# STM32F101 register map
File version: 1.2
CPU: CM3 r1p1, little endian, no MPU, no FPU, 4 interrupt priority bits
Registers are 32-bit, read-write, reset 0x0 unless marked. A register's access mark holds for its fields unless they carry their own. Offsets are from the block's base; [hi:lo] are bit positions; {n}, {i} and the like mark numbered series.

## USB — Universal serial bus full-speed device interface
Base 0x40005C00
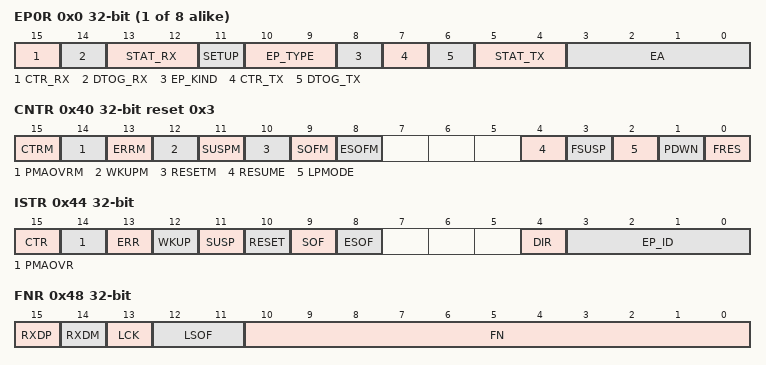
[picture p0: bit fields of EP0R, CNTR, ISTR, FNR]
{0x0+4i} EP{i}R (i=0..7) — endpoint {i} register
  [15] CTR_RX — Correct transfer for reception
  [14] DTOG_RX — Data Toggle, for reception transfers
  [13:12] STAT_RX — Status bits, for reception transfers
  [11] SETUP — Setup transaction completed
  [10:9] EP_TYPE — Endpoint type
  [8] EP_KIND — Endpoint kind
  [7] CTR_TX — Correct Transfer for transmission
  [6] DTOG_TX — Data Toggle, for transmission transfers
  [5:4] STAT_TX — Status bits, for transmission transfers
  [3:0] EA — Endpoint address
0x40 CNTR reset 0x3 — control register
  [15] CTRM — Correct transfer interrupt mask
  [14] PMAOVRM — Packet memory area over / underrun interrupt mask
  [13] ERRM — Error interrupt mask
  [12] WKUPM — Wakeup interrupt mask
  [11] SUSPM — Suspend mode interrupt mask
  [10] RESETM — USB reset interrupt mask
  [9] SOFM — Start of frame interrupt mask
  [8] ESOFM — Expected start of frame interrupt mask
  [4] RESUME — Resume request
  [3] FSUSP — Force suspend
  [2] LPMODE — Low-power mode
  [1] PDWN — Power down
  [0] FRES — Force USB Reset
0x44 ISTR — interrupt status register
  [15] CTR — Correct transfer
  [14] PMAOVR — Packet memory area over / underrun
  [13] ERR — Error
  [12] WKUP — Wakeup
  [11] SUSP — Suspend mode request
  [10] RESET — reset request
  [9] SOF — start of frame
  [8] ESOF — Expected start frame
  [4] DIR — Direction of transaction
  [3:0] EP_ID — Endpoint Identifier
0x48 FNR ro — frame number register
  [15] RXDP — Receive data + line status
  [14] RXDM — Receive data - line status
  [13] LCK — Locked
  [12:11] LSOF — Lost SOF
  [10:0] FN — Frame number
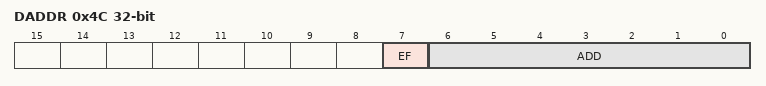
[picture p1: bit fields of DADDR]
0x4C DADDR — device address
  [7] EF — Enable function
  [6:0] ADD — Device address
0x50 BTABLE — Buffer table address
  [15:3] BTABLE — Buffer table

## SDIO — Secure digital input/output interface
Base 0x40018000
0x00 POWER — Bits 1:0 = PWRCTRL: Power supply control bits
  [1:0] PWRCTRL
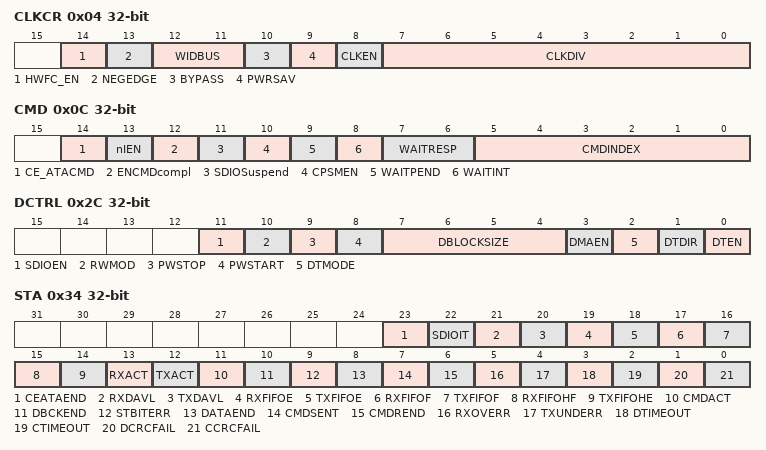
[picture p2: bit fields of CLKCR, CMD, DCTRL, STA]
0x04 CLKCR — SDI clock control register (SDIO_CLKCR)
  [14] HWFC_EN — HW Flow Control enable
  [13] NEGEDGE — SDIO_CK dephasing selection bit
  [12:11] WIDBUS — Wide bus mode enable bit
  [10] BYPASS — Clock divider bypass enable bit
  [9] PWRSAV — Power saving configuration bit
  [8] CLKEN — Clock enable bit
  [7:0] CLKDIV — Clock divide factor
0x08 ARG — Bits 31:0 = : Command argument
  [31:0] CMDARG — Command argument
0x0C CMD — SDIO command register (SDIO_CMD)
  [14] CE_ATACMD, [13] nIEN, [12] ENCMDcompl, [11] SDIOSuspend, [10] CPSMEN, [9] WAITPEND, [8] WAITINT, [7:6] WAITRESP, [5:0] CMDINDEX
0x10 RESPCMD ro — SDIO command register
  [5:0] RESPCMD
0x14 RESPI1 ro — Bits 31:0 = CARDSTATUS1
  [31:0] CARDSTATUS1
{0x10+4i} RESP{i} ro (i=2..4) — Bits 31:0 = CARDSTATUS{i}
  [31:0] CARDSTATUS{i}
0x24 DTIMER — Bits 31:0 = DATATIME: Data timeout period
  [31:0] DATATIME — Data timeout period
0x28 DLEN — Bits 24:0 = DATALENGTH: Data length value
  [24:0] DATALENGTH — Data length value
0x2C DCTRL — SDIO data control register (SDIO_DCTRL)
  [11] SDIOEN, [10] RWMOD, [9] PWSTOP, [8] PWSTART, [7:4] DBLOCKSIZE, [3] DMAEN, [2] DTMODE, [1] DTDIR, [0] DTEN
0x30 DCOUNT ro — Bits 24:0 = DATACOUNT: Data count value
  [24:0] DATACOUNT — Data count value
0x34 STA ro — SDIO status register (SDIO_STA)
  [23] CEATAEND, [22] SDIOIT, [21] RXDAVL, [20] TXDAVL, [19] RXFIFOE, [18] TXFIFOE, [17] RXFIFOF, [16] TXFIFOF, [15] RXFIFOHF, [14] TXFIFOHE, [13] RXACT, [12] TXACT, [11] CMDACT, [10] DBCKEND, [9] STBITERR, [8] DATAEND, [7] CMDSENT, [6] CMDREND, [5] RXOVERR, [4] TXUNDERR, [3] DTIMEOUT, [2] CTIMEOUT, [1] DCRCFAIL, [0] CCRCFAIL
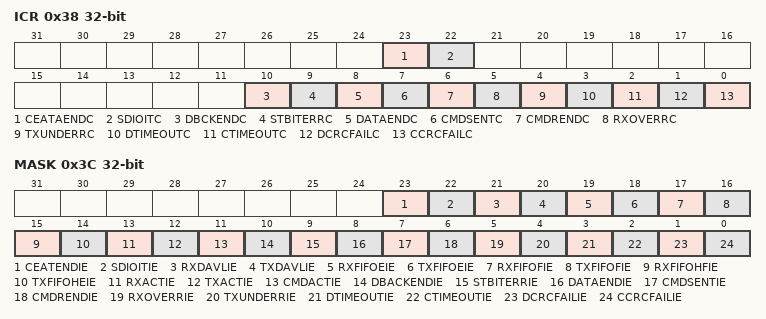
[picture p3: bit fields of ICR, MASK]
0x38 ICR — SDIO interrupt clear register (SDIO_ICR)
  [23] CEATAENDC, [22] SDIOITC, [10] DBCKENDC, [9] STBITERRC, [8] DATAENDC, [7] CMDSENTC, [6] CMDRENDC, [5] RXOVERRC, [4] TXUNDERRC, [3] DTIMEOUTC, [2] CTIMEOUTC, [1] DCRCFAILC, [0] CCRCFAILC
0x3C MASK — SDIO mask register (SDIO_MASK)
  [23] CEATENDIE, [22] SDIOITIE, [21] RXDAVLIE, [20] TXDAVLIE, [19] RXFIFOEIE, [18] TXFIFOEIE, [17] RXFIFOFIE, [16] TXFIFOFIE, [15] RXFIFOHFIE, [14] TXFIFOHEIE, [13] RXACTIE, [12] TXACTIE, [11] CMDACTIE, [10] DBACKENDIE, [9] STBITERRIE, [8] DATAENDIE, [7] CMDSENTIE, [6] CMDRENDIE, [5] RXOVERRIE, [4] TXUNDERRIE, [3] DTIMEOUTIE, [2] CTIMEOUTIE, [1] DCRCFAILIE, [0] CCRCFAILIE
0x48 FIFOCNT ro — Bits 23:0 = FIFOCOUNT: Remaining number of words to be written to or read from the FIFO
  [23:0] FIF0COUNT
0x80 FIFO — bits 31:0 = FIFOData: Receive and transmit FIFO data
  [31:0] FIFOData

## NVIC — Nested Vectored Interrupt Controller
Base 0xE000E100
0x00 ISER0 — Interrupt Set-Enable Register
  [31:0] SETENA
0x04 ISER1 — Interrupt Set-Enable Register
  [31:0] SETENA
0x80 ICER0 — Interrupt Clear-Enable Register
  [31:0] CLRENA
0x84 ICER1 — Interrupt Clear-Enable Register
  [31:0] CLRENA
0x100 ISPR0 — Interrupt Set-Pending Register
  [31:0] SETPEND
0x104 ISPR1 — Interrupt Set-Pending Register
  [31:0] SETPEND
0x180 ICPR0 — Interrupt Clear-Pending Register
  [31:0] CLRPEND
0x184 ICPR1 — Interrupt Clear-Pending Register
  [31:0] CLRPEND
0x200 IABR0 ro — Interrupt Active Bit Register
  [31:0] ACTIVE
0x204 IABR1 ro — Interrupt Active Bit Register
  [31:0] ACTIVE
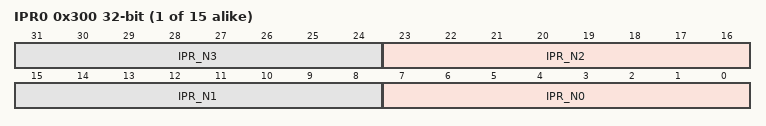
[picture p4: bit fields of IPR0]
{0x300+4i} IPR{i} (i=0..14) — Interrupt Priority Register
  [8n+7:8n] IPR_N{n} (n=0..3)

## MPU — Memory protection unit
Base 0xE000ED90
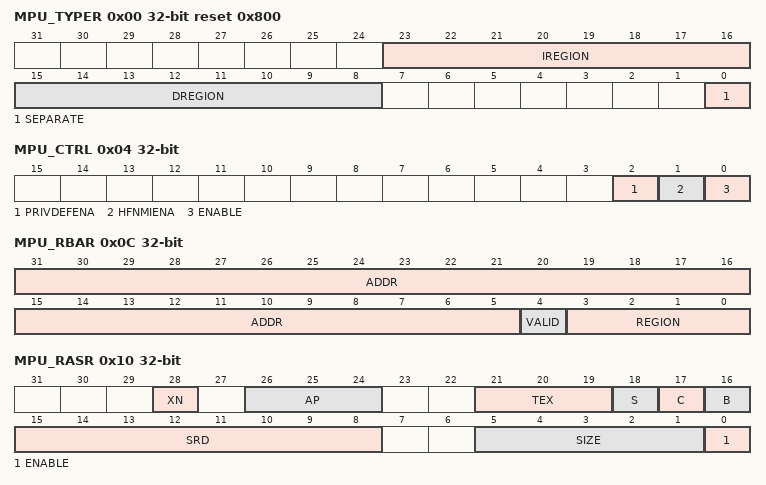
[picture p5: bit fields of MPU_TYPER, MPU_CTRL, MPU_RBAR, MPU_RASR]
0x00 MPU_TYPER ro reset 0x800 — MPU type register
  [23:16] IREGION — Number of MPU instruction regions
  [15:8] DREGION — Number of MPU data regions
  [0] SEPARATE — Separate flag
0x04 MPU_CTRL ro — MPU control register
  [2] PRIVDEFENA — Enable priviliged software access to default memory map
  [1] HFNMIENA — Enables the operation of MPU during hard fault
  [0] ENABLE — Enables the MPU
0x08 MPU_RNR — MPU region number register
  [7:0] REGION — MPU region
0x0C MPU_RBAR — MPU region base address register
  [31:5] ADDR — Region base address field
  [4] VALID — MPU region number valid
  [3:0] REGION — MPU region field
0x10 MPU_RASR — MPU region attribute and size register
  [28] XN — Instruction access disable bit
  [26:24] AP — Access permission
  [21:19] TEX — memory attribute
  [18] S — Shareable memory attribute
  [17] C — memory attribute
  [16] B — memory attribute
  [15:8] SRD — Subregion disable bits
  [5:1] SIZE — Size of the MPU protection region
  [0] ENABLE — Region enable bit.

## SCB_ACTRL — System control block ACTLR
Base 0xE000E008
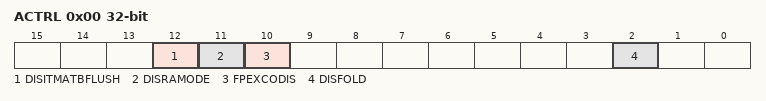
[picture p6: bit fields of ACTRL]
0x00 ACTRL — Auxiliary control register
  [12] DISITMATBFLUSH, [11] DISRAMODE, [10] FPEXCODIS, [2] DISFOLD

## NVIC_STIR — Nested vectored interrupt controller
Base 0xE000EF00
0x00 STIR — Software trigger interrupt register
  [8:0] INTID — Software generated interrupt ID

## STK — SysTick timer
Base 0xE000E010
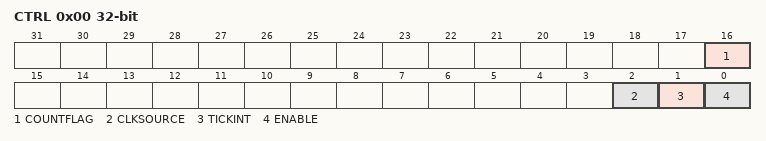
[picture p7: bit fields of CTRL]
0x00 CTRL — SysTick control and status register
  [16] COUNTFLAG
  [2] CLKSOURCE — Clock source selection
  [1] TICKINT — SysTick exception request enable
  [0] ENABLE — Counter enable
0x04 LOAD_ — SysTick reload value register
  [23:0] RELOAD — RELOAD value
0x08 VAL — SysTick current value register
  [23:0] CURRENT — Current counter value
0x0C CALIB — SysTick calibration value register
  [23:0] TENMS — Calibration value
